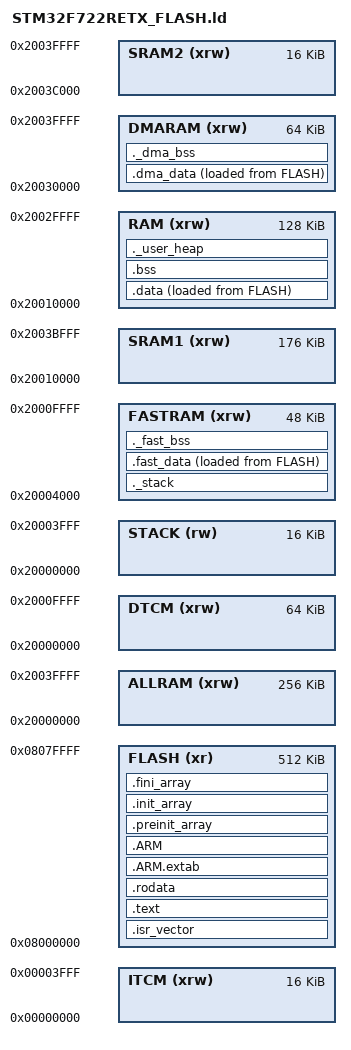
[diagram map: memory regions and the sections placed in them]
/*
******************************************************************************
**
** @file        : LinkerScript.ld
**
** @author      : Auto-generated by STM32CubeIDE
**
** @brief       : Linker script for STM32F722RETx Device from STM32F7 series
**                      512KBytes FLASH
**                      256KBytes RAM
**
**                Set heap size, stack size and stack location according
**                to application requirements.
**
**                Set memory bank area and size if external memory is used
**
**  Target      : STMicroelectronics STM32
**
**  Distribution: The file is distributed as is, without any warranty
**                of any kind.
**
******************************************************************************
** @attention
**
** Copyright (c) 2024 STMicroelectronics.
** All rights reserved.
**
** This software is licensed under terms that can be found in the LICENSE file
** in the root directory of this software component.
** If no LICENSE file comes with this software, it is provided AS-IS.
**
******************************************************************************
**
** Modifications by Douglas P. Fields, Jr. 2025-01-25,
** available under Apache 2.0 license - see README.md file.
** 
** TODO:
** * Set up DMARAM sections for data and BSS
*/

/**
 * References:
 * DS11853 Rev 9 - Data Sheet
 * RM0431 Rev 3 - Reference Manual
 * nucleo-uart - https://github.com/LispEngineer/nucleo-uart/blob/main/STM32F767ZITX_FLASH.ld
 *   (This uses an STM32F767ZIxx)
 *
 * RM0431 Section 1.6 - Embedded SRAM
 *   DTCM-RAM on TCM interface (Data Tightly Coupled Memory)
 *     0x2000 0000 64KB
 *   SRAM1
 *     0x2001 0000 176KB
 *   SRAM2
 *     0x2003 C000 16KB
 *   ITCM-RAM - accessible only by CPU
 *     0x0000 0000 to 0x0000 3FFF (16KB)
 *
 * Concurrent SRAM accesses to SRAM1 and 2
 * I/DTCM RAM can be accessed 64 bits at a time; the others 32 bits
 * 
 * Flash on AXIM interface is at 0x0800 0000 (RM p77)
 */ 
 
/**
 * Intended usage:
 *
 * ITCM - managed by the system
 * 
 * DTCM 
 *   - Stack
 *   - I2S data
 *
 * SRAM1 & 2
 *   - Heap
 *   - Everything else
 *
 * We do a LOT of DMA for UART and SPI and I2S.
 * Hence, it's easier not to enable the data cache,
 * as that will ensure that the DMA controller will
 * always read from Memory correctly instead of stale
 * data from unflushed (dirty) cache lines in L1 cache.
 *
 * As a TODO, though, we could enable data caching and
 * every time we write to a DMA buffer, we could tell
 * the processor to flush the appropriate parts of the
 * L1 data cache, and every time we read from a DMA buffer
 * we could tell it to clear the cache.
 * We can use the DMB and DSB instructions to implement this.
 * (See ARM: https://developer.arm.com/documentation/ddi0406/c/Application-Level-Architecture/Application-Level-Memory-Model/Memory-access-order/Memory-barriers?lang=en
 *  and https://developer.arm.com/documentation/101051/0101/Memory-system/Instruction-and-data-cache - but that's for the Cortex-M55)
 * We can also use CMSIS D-Cache functions.
 * (See ARM: https://arm-software.github.io/CMSIS_6/latest/Core/group__Dcache__functions__m7.html,
 *  specifically SCB_InvalidateDCache_by_Addr)
 *
 * Minor note: A 320x240 display has 75k pixels, so
 * a 16-bit framebuffer would take 150kB!
 */
 
/**
 * Migration to STM32H7 notes:
 * "The default memory used by most of ST projects is DTCM which is not accessible by DMA in STM32H7 devices."
 * See: https://community.st.com/t5/stm32-mcus-products/confused-about-dma-and-cache-on-stm32-h7-devices/td-p/178674
 */
 
/* Entry Point */
ENTRY(Reset_Handler)

/* Highest address of the user mode stack. 
 * TODO: Make this purely in DTCM for speed,
 * and make it a fixed size.
 */
_estack = ORIGIN(STACK) + LENGTH(STACK); /* end of "STACK" RAM type memory (start of DTCM) */
_eheap = ORIGIN(RAM) + LENGTH(RAM); /* End of normal RAM type memory (end of the heap) */

_Min_Heap_Size = 0x200; /* required amount of heap */
_DTCM_Stack_Size = 0x4000; /* 16 KB */
_DMARAM_Size = 0x10000; /* 64 KB */

/** Here is our memory layout
 *
 * DTCM             STACK (size above)
 *                  FASTRAM (remainder of DTCM)
 * SRAM1            BSS, DATA
 *                  HEAP
 *                  DMARAM
 * SRAM2            DMARAM (continued)
 */

/* Memories definition */
MEMORY
{
  /* Here's all our (data) memory */
  ALLRAM  (xrw)    : ORIGIN = 0x20000000,   LENGTH = 256K /* The original RAM defined in linker script */
  
  /* Here are our individual RAM blocks */
  ITCM    (xrw)    : ORIGIN = 0x00000000,   LENGTH = 16K
  DTCM    (xrw)    : ORIGIN = 0x20000000,   LENGTH = 64K
  SRAM1   (xrw)    : ORIGIN = 0x20010000,   LENGTH = 176K
  SRAM2   (xrw)    : ORIGIN = 0x2003C000,   LENGTH = 16K

  /* Here's the flash - program storage and constant data. */
  FLASH   (xr)     : ORIGIN = 0x08000000,   LENGTH = 512K

  /* The Stack is in DTCM for speed.
   * Then, there is "FASTRAM" in DTCM for other things that have
   * to be fast.
   * DTCM size total is 64K. 
   */
  STACK   (rw)     : ORIGIN = ORIGIN(DTCM),   LENGTH = _DTCM_Stack_Size /* DTCM bottom */
  FASTRAM (xrw)    : ORIGIN = ORIGIN(DTCM) + _DTCM_Stack_Size, LENGTH = LENGTH(DTCM) - _DTCM_Stack_Size /* DTCM TOP */

  /* Then there is slow RAM after DTCM, of size 176K + 16K
   * which is 64K x 3. */
  RAM     (xrw)    : ORIGIN = ORIGIN(SRAM1),   LENGTH = LENGTH(SRAM1) + LENGTH(SRAM2) - _DMARAM_Size
  
  /* Finally there is DMA RAM which is non-cached.
   * This happens to cover both SRAM1 and SRAM2.
   * We configure the MPU not to cache this memory,
   * so we can use it with impunity for DMA. */
  DMARAM  (xrw)    : ORIGIN = ORIGIN(RAM) + LENGTH(RAM),   LENGTH = _DMARAM_Size
}

/* Sections */
SECTIONS
{
  /* The startup code into "FLASH" Rom type memory */
  .isr_vector :
  {
    . = ALIGN(4);
    KEEP(*(.isr_vector)) /* Startup code */
    . = ALIGN(4);
  } >FLASH

  /* The program code and other data into "FLASH" Rom type memory */
  .text :
  {
    . = ALIGN(4);
    *(.text)           /* .text sections (code) */
    *(.text*)          /* .text* sections (code) */
    *(.glue_7)         /* glue arm to thumb code */
    *(.glue_7t)        /* glue thumb to arm code */
    *(.eh_frame)

    KEEP (*(.init))
    KEEP (*(.fini))

    . = ALIGN(4);
    _etext = .;        /* define a global symbols at end of code */
  } >FLASH

  /* Constant data into "FLASH" Rom type memory */
  .rodata :
  {
    . = ALIGN(4);
    *(.rodata)         /* .rodata sections (constants, strings, etc.) */
    *(.rodata*)        /* .rodata* sections (constants, strings, etc.) */
    . = ALIGN(4);
  } >FLASH

  .ARM.extab (READONLY) : /* The "READONLY" keyword is only supported in GCC11 and later, remove it if using GCC10 or earlier. */
  {
    . = ALIGN(4);
    *(.ARM.extab* .gnu.linkonce.armextab.*)
    . = ALIGN(4);
  } >FLASH

  .ARM (READONLY) : /* The "READONLY" keyword is only supported in GCC11 and later, remove it if using GCC10 or earlier. */
  {
    . = ALIGN(4);
    __exidx_start = .;
    *(.ARM.exidx*)
    __exidx_end = .;
    . = ALIGN(4);
  } >FLASH

  .preinit_array (READONLY) : /* The "READONLY" keyword is only supported in GCC11 and later, remove it if using GCC10 or earlier. */
  {
    . = ALIGN(4);
    PROVIDE_HIDDEN (__preinit_array_start = .);
    KEEP (*(.preinit_array*))
    PROVIDE_HIDDEN (__preinit_array_end = .);
    . = ALIGN(4);
  } >FLASH

  .init_array (READONLY) : /* The "READONLY" keyword is only supported in GCC11 and later, remove it if using GCC10 or earlier. */
  {
    . = ALIGN(4);
    PROVIDE_HIDDEN (__init_array_start = .);
    KEEP (*(SORT(.init_array.*)))
    KEEP (*(.init_array*))
    PROVIDE_HIDDEN (__init_array_end = .);
    . = ALIGN(4);
  } >FLASH

  .fini_array (READONLY) : /* The "READONLY" keyword is only supported in GCC11 and later, remove it if using GCC10 or earlier. */
  {
    . = ALIGN(4);
    PROVIDE_HIDDEN (__fini_array_start = .);
    KEEP (*(SORT(.fini_array.*)))
    KEEP (*(.fini_array*))
    PROVIDE_HIDDEN (__fini_array_end = .);
    . = ALIGN(4);
  } >FLASH

  /* Used by the startup to initialize data, fastdata & dmadata.
   * It's unlikely there will be much dmadata though! */
  /* Per manual: Return the absolute load address of the named section. This is 
   * normally the same as ADDR, but it may be different if the AT keyword is used 
   * in the section definition (see section Optional Section Attributes). */
  _sidata = LOADADDR(.data);
  _sifastdata = LOADADDR(.fast_data);
  _sidmadata = LOADADDR(.dma_data);
  
  /* Symbols related to FASTRAM which is located in the DTCM:
   * _sifastdata = the LOADADDR of the .fast_data segment
   * _sfastdata = the actual aligned start of the fast data
   * _efastdata = the aligned end of the fast data
   * _sfbss = Pre-aligned start of the fast bss
   * _efbss = Post-aligned end of the fast bss
   */

  /* Initialized data sections into "RAM" Ram type memory */
  .data :
  {
    . = ALIGN(4);
    _sdata = .;        /* create a global symbol at data start */
    *(.data)           /* .data sections */
    *(.data*)          /* .data* sections */
    *(.RamFunc)        /* .RamFunc sections */
    *(.RamFunc*)       /* .RamFunc* sections */

    . = ALIGN(4);
    _edata = .;        /* define a global symbol at data end */

  } >RAM AT> FLASH

  /* Uninitialized data section into "RAM" Ram type memory */
  . = ALIGN(4);
  .bss :
  {
    /* This is used by the startup in order to initialize the .bss section */
    _sbss = .;         /* define a global symbol at bss start */
    __bss_start__ = _sbss;
    *(.bss)
    *(.bss*)
    *(COMMON)

    . = ALIGN(4);
    _ebss = .;         /* define a global symbol at bss end */
    __bss_end__ = _ebss;
  } >RAM

  /* User_heap section, used to check that there is enough "RAM" Ram  type memory left.
   * Stack is allocated separately. */
  ._user_heap :
  {
    . = ALIGN(8);
    PROVIDE ( end = . );
    PROVIDE ( _end = . );
    . = . + _Min_Heap_Size;
    . = ALIGN(8);
  } >RAM
  
  ._stack :
  {
    PROVIDE ( _stack_start = . );
    . = . + _DTCM_Stack_Size;
    PROVIDE ( _stack_end = . );
  } >FASTRAM
  
  /* Initialized data sections into "FASTRAM" DTCM type memory */
  .fast_data :
  {
    . = ALIGN(4);
    _sfastdata = .;        /* create a global symbol at data start */
    *(.fast_data)          /* .fast_data sections */
    *(.fast_data*)         /* .fast_data* sections */
    . = ALIGN(4);
    _efastdata = .;        /* define a global symbol at data end */

  } >FASTRAM AT> FLASH

  /* Unnitialized (zero-initialized) data sections into "FASTRAM" DTCM type memory */
  ._fast_bss :
  {
    _sfbss = .;
    . = ALIGN(4);
    *(.fast_bss)
    *(.fast_bss*)
    . = ALIGN(4);
    _efbss = .;
  } >FASTRAM

  /* Initialized data sections into "DMARAM" non-cached memory */
  .dma_data :
  {
    . = ALIGN(4);
    _sdmadata = .;        /* create a global symbol at data start */
    *(.dma_data)          /* .fast_data sections */
    *(.dma_data*)         /* .fast_data* sections */
    . = ALIGN(4);
    _edmadata = .;        /* define a global symbol at data end */

  } >DMARAM AT> FLASH

  /* Unnitialized (zero-initialized) data sections into "DMARAM" non-cached memory */
  ._dma_bss :
  {
    _sdmabss = .;
    . = ALIGN(4);
    *(.dma_bss)
    *(.dma_bss*)
    . = ALIGN(4);
    _edmabss = .;
  } >DMARAM
  

  /* Remove information from the compiler libraries */
  /DISCARD/ :
  {
    libc.a ( * )
    libm.a ( * )
    libgcc.a ( * )
  }

  .ARM.attributes 0 : { *(.ARM.attributes) }
}
